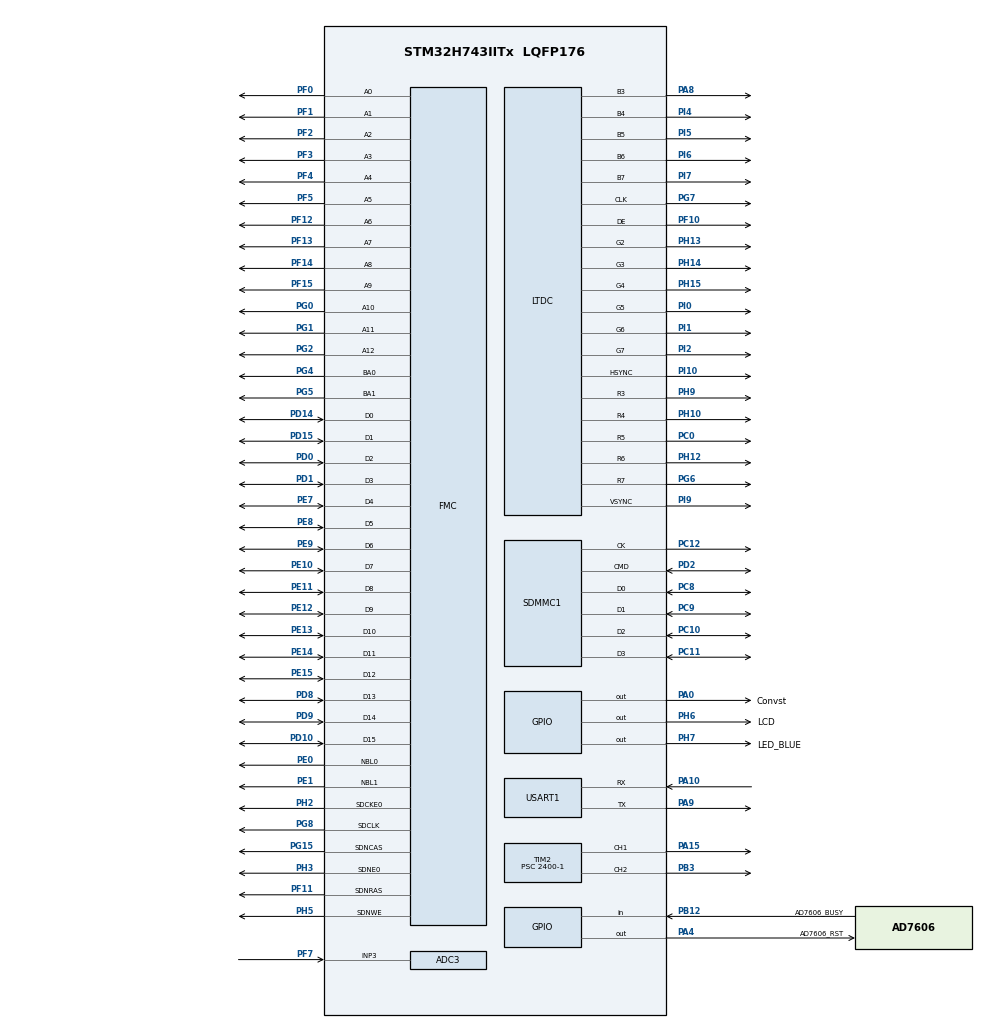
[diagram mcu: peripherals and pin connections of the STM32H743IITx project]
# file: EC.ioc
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ADC3.Channel-1\#ChannelRegularConversion=ADC_CHANNEL_3
ADC3.NbrOfConversionFlag=1
ADC3.OffsetNumber-1\#ChannelRegularConversion=ADC_OFFSET_NONE
ADC3.OffsetSignedSaturation-1\#ChannelRegularConversion=DISABLE
ADC3.Rank-1\#ChannelRegularConversion=1
ADC3.SamplingTime-1\#ChannelRegularConversion=ADC_SAMPLETIME_1CYCLE_5
Bdma.ADC3.0.Direction=DMA_PERIPH_TO_MEMORY
Bdma.ADC3.0.EventEnable=DISABLE
Bdma.ADC3.0.Instance=BDMA_Channel0
Bdma.ADC3.0.MemDataAlignment=DMA_MDATAALIGN_HALFWORD
Bdma.ADC3.0.MemInc=DMA_MINC_ENABLE
Bdma.ADC3.0.Mode=DMA_NORMAL
Bdma.ADC3.0.PeriphDataAlignment=DMA_PDATAALIGN_HALFWORD
Bdma.ADC3.0.PeriphInc=DMA_PINC_DISABLE
Bdma.ADC3.0.Polarity=HAL_DMAMUX_REQ_GEN_RISING
Bdma.ADC3.0.Priority=DMA_PRIORITY_LOW
Bdma.ADC3.0.RequestNumber=1
Bdma.ADC3.0.SignalID=NONE
Bdma.ADC3.0.SyncEnable=DISABLE
Bdma.ADC3.0.SyncPolarity=HAL_DMAMUX_SYNC_NO_EVENT
Bdma.ADC3.0.SyncRequestNumber=1
Bdma.ADC3.0.SyncSignalID=NONE
Bdma.Request0=ADC3
Bdma.RequestsNb=1
CORTEX_M7.AccessPermission-Cortex_Memory_Protection_Unit_Region2_Settings=MPU_REGION_FULL_ACCESS
CORTEX_M7.AccessPermission-Cortex_Memory_Protection_Unit_Region4_Settings=MPU_REGION_FULL_ACCESS
CORTEX_M7.BaseAddress-Cortex_Memory_Protection_Unit_Region2_Settings=0xC0000000
CORTEX_M7.BaseAddress-Cortex_Memory_Protection_Unit_Region4_Settings=0xC0000000
CORTEX_M7.CPU_DCache=Enabled
CORTEX_M7.CPU_ICache=Enabled
CORTEX_M7.Enable-Cortex_Memory_Protection_Unit_Region2_Settings=MPU_REGION_ENABLE
CORTEX_M7.Enable-Cortex_Memory_Protection_Unit_Region4_Settings=MPU_REGION_ENABLE
CORTEX_M7.IsCacheable-Cortex_Memory_Protection_Unit_Region2_Settings=MPU_ACCESS_CACHEABLE
CORTEX_M7.IsCacheable-Cortex_Memory_Protection_Unit_Region4_Settings=MPU_ACCESS_CACHEABLE
CORTEX_M7.MPU_Control=MPU_PRIVILEGED_DEFAULT
CORTEX_M7.Size-Cortex_Memory_Protection_Unit_Region2_Settings=MPU_REGION_SIZE_32MB
CORTEX_M7.Size-Cortex_Memory_Protection_Unit_Region4_Settings=MPU_REGION_SIZE_32MB
CORTEX_M7.SubRegionDisable-Cortex_Memory_Protection_Unit_Region2_Settings=0x00
DMA2D.ColorMode=DMA2D_OUTPUT_RGB565
DMA2D.Mode=DMA2D_R2M
FMC.CASLatency1=FMC_SDRAM_CAS_LATENCY_3
FMC.ColumnBitsNumber1=FMC_SDRAM_COLUMN_BITS_NUM_9
FMC.ExitSelfRefreshDelay1=7
FMC.LoadToActiveDelay1=2
FMC.RCDDelay1=2
FMC.RPDelay1=2
FMC.ReadBurst1=FMC_SDRAM_RBURST_ENABLE
FMC.ReadPipeDelay1=FMC_SDRAM_RPIPE_DELAY_1
FMC.RowCycleDelay1=7
FMC.SDClockPeriod1=FMC_SDRAM_CLOCK_PERIOD_2
FMC.SelfRefreshTime1=4
FMC.WriteRecoveryTime1=3
LTDC.ActiveH=272
LTDC.ActiveW=480
LTDC.Alpha_L0=255
LTDC.Alpha_L1=255
LTDC.BlendingFactor1_L1=LTDC_BLENDING_FACTOR1_PAxCA
LTDC.BlendingFactor2_L1=LTDC_BLENDING_FACTOR2_PAxCA
LTDC.Blue=0
LTDC.Blue_L0=0
LTDC.Blue_L1=0
LTDC.FBStartAdress_L0=0xC0000000
LTDC.FBStartAdress_L1=0xCC000000
LTDC.HBP=43
LTDC.HFP=8
LTDC.HSync=1
LTDC.ImageHeight_L0=272
LTDC.ImageHeight_L1=272
LTDC.ImageWidth_L0=480
LTDC.Layers=0
LTDC.PixelFormat_L0=LTDC_PIXEL_FORMAT_RGB565
LTDC.Red=0
LTDC.VBP=12
LTDC.VFP=8
LTDC.VSync=1
LTDC.WindowX1_L0=480
LTDC.WindowX1_L1=480
LTDC.WindowY1_L0=272
LTDC.WindowY1_L1=272
Mcu.Family=STM32H7
Mcu.Name=STM32H743IITx
Mcu.Package=LQFP176
NVIC.BDMA_Channel0_IRQn=true\:0\:0\:false\:false\:true\:false\:true
NVIC.DMA2D_IRQn=true\:6\:0\:true\:false\:true\:true\:true
NVIC.FMC_IRQn=true\:0\:0\:false\:false\:true\:true\:true
NVIC.LTDC_IRQn=true\:6\:0\:true\:false\:true\:true\:true
NVIC.PriorityGroup=NVIC_PRIORITYGROUP_4
NVIC.SDMMC1_IRQn=true\:0\:0\:false\:false\:true\:true\:true
NVIC.USART1_IRQn=true\:0\:0\:false\:false\:true\:true\:true
PA0.GPIO_Label=Convst
PA0.GPIO_PuPd=GPIO_NOPULL
PA0.Signal=GPIO_Output
PA10.GPIO_PuPd=GPIO_PULLUP
PA10.GPIO_Speed=GPIO_SPEED_FREQ_VERY_HIGH
PA10.Mode=Asynchronous
PA10.Signal=USART1_RX
PA13\ (JTMS/SWDIO).Mode=Serial_Wire
PA13\ (JTMS/SWDIO).Signal=DEBUG_JTMS-SWDIO
PA14\ (JTCK/SWCLK).Mode=Serial_Wire
PA14\ (JTCK/SWCLK).Signal=DEBUG_JTCK-SWCLK
PA15\ (JTDI).GPIO_PuPd=GPIO_NOPULL
PA15\ (JTDI).Signal=S_TIM2_CH1
PA2.Signal=LTDC_R1
PA4.GPIO_Label=AD7606_RST
PA4.Signal=GPIO_Output
PA8.Mode=RGB565
PA8.Signal=LTDC_B3
PA9.GPIO_PuPd=GPIO_PULLUP
PA9.GPIO_Speed=GPIO_SPEED_FREQ_VERY_HIGH
PA9.Mode=Asynchronous
PA9.Signal=USART1_TX
PB12.GPIO_Label=AD7606_BUSY
PB12.GPIO_PuPd=GPIO_NOPULL
PB12.Signal=GPIO_Input
PB3\ (JTDO/TRACESWO).GPIO_PuPd=GPIO_NOPULL
PB3\ (JTDO/TRACESWO).Signal=S_TIM2_CH2
PC0.Mode=RGB565
PC0.Signal=LTDC_R5
PC10.Mode=SD_4_bits_Wide_bus
PC10.Signal=SDMMC1_D2
PC11.Mode=SD_4_bits_Wide_bus
PC11.Signal=SDMMC1_D3
PC12.Mode=SD_4_bits_Wide_bus
PC12.Signal=SDMMC1_CK
PC8.GPIO_PuPd=GPIO_PULLUP
PC8.Mode=SD_4_bits_Wide_bus
PC8.Signal=SDMMC1_D0
PC9.Mode=SD_4_bits_Wide_bus
PC9.Signal=SDMMC1_D1
PD0.Signal=FMC_D2_DA2
PD1.Signal=FMC_D3_DA3
PD10.Signal=FMC_D15_DA15
PD14.Signal=FMC_D0_DA0
PD15.Signal=FMC_D1_DA1
PD2.Mode=SD_4_bits_Wide_bus
PD2.Signal=SDMMC1_CMD
PD6.Signal=LTDC_B2
PD8.Signal=FMC_D13_DA13
PD9.Signal=FMC_D14_DA14
PE0.Signal=FMC_NBL0
PE1.Signal=FMC_NBL1
PE10.Signal=FMC_D7_DA7
PE11.Signal=FMC_D8_DA8
PE12.Signal=FMC_D9_DA9
PE13.Signal=FMC_D10_DA10
PE14.Signal=FMC_D11_DA11
PE15.Signal=FMC_D12_DA12
PE6.Signal=LTDC_G1
PE7.Signal=FMC_D4_DA4
PE8.Signal=FMC_D5_DA5
PE9.Signal=FMC_D6_DA6
PF0.Signal=FMC_A0
PF1.Signal=FMC_A1
PF10.Mode=RGB565
PF10.Signal=LTDC_DE
PF11.Signal=FMC_SDNRAS
PF12.Signal=FMC_A6
PF13.Signal=FMC_A7
PF14.Signal=FMC_A8
PF15.Signal=FMC_A9
PF2.Signal=FMC_A2
PF3.Signal=FMC_A3
PF4.Signal=FMC_A4
PF5.Signal=FMC_A5
PF7.Mode=IN3-Single-Ended
PF7.Signal=ADC3_INP3
PG0.Signal=FMC_A10
PG1.Signal=FMC_A11
PG12.Signal=LTDC_B1
PG13.Signal=LTDC_R0
PG14.Signal=LTDC_B0
PG15.Signal=FMC_SDNCAS
PG2.Signal=FMC_A12
PG4.Signal=FMC_A14_BA0
PG5.Signal=FMC_A15_BA1
PG6.Mode=RGB565
PG6.Signal=LTDC_R7
PG7.Mode=RGB565
PG7.Signal=LTDC_CLK
PG8.Signal=FMC_SDCLK
PH0-OSC_IN\ (PH0).Mode=HSE-External-Oscillator
PH0-OSC_IN\ (PH0).Signal=RCC_OSC_IN
PH1-OSC_OUT\ (PH1).Mode=HSE-External-Oscillator
PH1-OSC_OUT\ (PH1).Signal=RCC_OSC_OUT
PH10.Mode=RGB565
PH10.Signal=LTDC_R4
PH12.Mode=RGB565
PH12.Signal=LTDC_R6
PH13.Mode=RGB565
PH13.Signal=LTDC_G2
PH14.Mode=RGB565
PH14.Signal=LTDC_G3
PH15.Mode=RGB565
PH15.Signal=LTDC_G4
PH2.Mode=SdramChipSelect1_1
PH2.Signal=FMC_SDCKE0
PH3.Mode=SdramChipSelect1_1
PH3.Signal=FMC_SDNE0
PH5.Signal=FMC_SDNWE
PH6.GPIO_Label=LCD
PH6.GPIO_ModeDefaultOutputPP=GPIO_MODE_OUTPUT_PP
PH6.GPIO_PuPd=GPIO_PULLUP
PH6.PinState=GPIO_PIN_SET
PH6.Signal=GPIO_Output
PH7.GPIO_Label=LED_BLUE
PH7.GPIO_PuPd=GPIO_PULLUP
PH7.Signal=GPIO_Output
PH8.Signal=LTDC_R2
PH9.Mode=RGB565
PH9.Signal=LTDC_R3
PI0.Mode=RGB565
PI0.Signal=LTDC_G5
PI1.Mode=RGB565
PI1.Signal=LTDC_G6
PI10.Mode=RGB565
PI10.Signal=LTDC_HSYNC
PI2.Mode=RGB565
PI2.Signal=LTDC_G7
PI4.Mode=RGB565
PI4.Signal=LTDC_B4
PI5.Mode=RGB565
PI5.Signal=LTDC_B5
PI6.Mode=RGB565
PI6.Signal=LTDC_B6
PI7.Mode=RGB565
PI7.Signal=LTDC_B7
PI9.Mode=RGB565
PI9.Signal=LTDC_VSYNC
ProjectManager.HeapSize=0x200
ProjectManager.StackSize=0x400
ProjectManager.TargetToolchain=SW4STM32
RCC.ADCFreq_Value=75000000
RCC.APB1Freq_Value=120000000
RCC.APB2Freq_Value=120000000
RCC.APB3Freq_Value=120000000
RCC.APB4Freq_Value=120000000
RCC.CortexFreq_Value=480000000
RCC.D1PPRE=RCC_APB3_DIV2
RCC.D2PPRE1=RCC_APB1_DIV2
RCC.D2PPRE2=RCC_APB2_DIV2
RCC.D3PPRE=RCC_APB4_DIV2
RCC.DIVM1=5
RCC.DIVM2=2
RCC.DIVM3=1
RCC.DIVN1=192
RCC.DIVN2=12
RCC.DIVN3=6
RCC.DIVQ1=4
RCC.DIVR3=1
RCC.FLatency=FLASH_LATENCY_4
RCC.HCLKFreq_Value=240000000
RCC.HPRE=RCC_HCLK_DIV2
RCC.PLL1_VCI_Range-AdvancedSettings=RCC_PLL1VCIRANGE_0
RCC.PLL2FRACN=0
RCC.PLL2_VCI_Range-AdvancedSettings=RCC_PLL2VCIRANGE_2
RCC.PLL2_VCO_SEL-AdvancedSettings=RCC_PLL2VCOMEDIUM
RCC.PLL3FRACN=0
RCC.PLL3_VCI_Range-AdvancedSettings=RCC_PLL3VCIRANGE_0
RCC.PLLFRACN=0
RCC.PLLSourceVirtual=RCC_PLLSOURCE_HSE
RCC.PWR_Regulator_Voltage_Scale=PWR_REGULATOR_VOLTAGE_SCALE0
RCC.SYSCLKFreq_VALUE=480000000
RCC.SYSCLKSource=RCC_SYSCLKSOURCE_PLLCLK
RCC.USBFreq_Value=240000000
SDMMC1.ClockDiv=2
SDMMC1.HardwareFlowControl=SDMMC_HARDWARE_FLOW_CONTROL_ENABLE
SH.FMC_A0.0=FMC_A0,13b-sda1
SH.FMC_A1.0=FMC_A1,13b-sda1
SH.FMC_A10.0=FMC_A10,13b-sda1
SH.FMC_A11.0=FMC_A11,13b-sda1
SH.FMC_A12.0=FMC_A12,13b-sda1
SH.FMC_A14_BA0.0=FMC_BA0,FourSdramBanks1
SH.FMC_A15_BA1.0=FMC_BA1,FourSdramBanks1
SH.FMC_A2.0=FMC_A2,13b-sda1
SH.FMC_A3.0=FMC_A3,13b-sda1
SH.FMC_A4.0=FMC_A4,13b-sda1
SH.FMC_A5.0=FMC_A5,13b-sda1
SH.FMC_A6.0=FMC_A6,13b-sda1
SH.FMC_A7.0=FMC_A7,13b-sda1
SH.FMC_A8.0=FMC_A8,13b-sda1
SH.FMC_A9.0=FMC_A9,13b-sda1
SH.FMC_D0_DA0.0=FMC_D0,sd-16b-d1
SH.FMC_D10_DA10.0=FMC_D10,sd-16b-d1
SH.FMC_D11_DA11.0=FMC_D11,sd-16b-d1
SH.FMC_D12_DA12.0=FMC_D12,sd-16b-d1
SH.FMC_D13_DA13.0=FMC_D13,sd-16b-d1
SH.FMC_D14_DA14.0=FMC_D14,sd-16b-d1
SH.FMC_D15_DA15.0=FMC_D15,sd-16b-d1
SH.FMC_D1_DA1.0=FMC_D1,sd-16b-d1
SH.FMC_D2_DA2.0=FMC_D2,sd-16b-d1
SH.FMC_D3_DA3.0=FMC_D3,sd-16b-d1
SH.FMC_D4_DA4.0=FMC_D4,sd-16b-d1
SH.FMC_D5_DA5.0=FMC_D5,sd-16b-d1
SH.FMC_D6_DA6.0=FMC_D6,sd-16b-d1
SH.FMC_D7_DA7.0=FMC_D7,sd-16b-d1
SH.FMC_D8_DA8.0=FMC_D8,sd-16b-d1
SH.FMC_D9_DA9.0=FMC_D9,sd-16b-d1
SH.FMC_NBL0.0=FMC_NBL0,Sd2ByteEnable1
SH.FMC_NBL1.0=FMC_NBL1,Sd2ByteEnable1
SH.FMC_SDCLK.0=FMC_SDCLK,13b-sda1
SH.FMC_SDNCAS.0=FMC_SDNCAS,13b-sda1
SH.FMC_SDNRAS.0=FMC_SDNRAS,13b-sda1
SH.FMC_SDNWE.0=FMC_SDNWE,13b-sda1
SH.S_TIM2_CH1.0=TIM2_CH1,PWM Generation1 CH1
SH.S_TIM2_CH2.0=TIM2_CH2,PWM Generation2 CH2
STMicroelectronics.X-CUBE-ALGOBUILD.1.2.1.LibraryCcDSPOoLibraryJjDSPOoLibrary=true
TIM2.Channel-PWM\ Generation1\ CH1=TIM_CHANNEL_1
TIM2.Channel-PWM\ Generation2\ CH2=TIM_CHANNEL_2
TIM2.Period=100
TIM2.Prescaler=2400-1
TIM2.Pulse-PWM\ Generation1\ CH1=1
TIM2.Pulse-PWM\ Generation2\ CH2=1
USART1.VirtualMode-Asynchronous=VM_ASYNC
VP_DMA2D_VS_DMA2D.Mode=DMA2D_Activate
VP_STMicroelectronics.X-CUBE-ALGOBUILD_VS_DSPOoLibraryJjLibrary_1.2.1_1.2.1.Mode=DSPOoLibraryJjLibrary
board=custom

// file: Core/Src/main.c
/* USER CODE BEGIN Header */
/**
  ******************************************************************************
  * @file           : main.c
  * @brief          : Main program body
  ******************************************************************************
  * @attention
  *
  * <h2><center>&copy; Copyright (c) 2021 STMicroelectronics.
  * All rights reserved.</center></h2>
  *
  * This software component is licensed by ST under Ultimate Liberty license
  * SLA0044, the "License"; You may not use this file except in compliance with
  * the License. You may obtain a copy of the License at:
  *                             www.st.com/SLA0044
  *
  ******************************************************************************
  */
/* USER CODE END Header */
#include "main.h"
#include "adc.h"
#include "bdma.h"
#include "dma2d.h"
#include "ltdc.h"
#include "sdmmc.h"
#include "tim.h"
#include "usart.h"
#include "gpio.h"
#include "fmc.h"

/* USER CODE BEGIN Includes */
#include "arm_math.h"
/* USER CODE END Includes */

void SystemClock_Config(void);
static void MPU_Config(void);

int main(void)
{

  /* MPU Configuration--------------------------------------------------------*/
  MPU_Config();

  /* Enable I-Cache---------------------------------------------------------*/
  SCB_EnableICache();

  /* Enable D-Cache---------------------------------------------------------*/
  SCB_EnableDCache();

  /* MCU Configuration--------------------------------------------------------*/

  /* Reset of all peripherals, Initializes the Flash interface and the Systick. */
  HAL_Init();

  /* Configure the system clock */
  SystemClock_Config();

  /* Initialize all configured peripherals */
  MX_GPIO_Init();
  MX_LTDC_Init();
  MX_FMC_Init();
  MX_DMA2D_Init();
  MX_USART1_UART_Init();
  MX_SDMMC1_SD_Init();
  MX_BDMA_Init();
  MX_ADC3_Init();
  MX_TIM2_Init();
  /* USER CODE BEGIN 2 */
    PowerPhaseRadians_f32
  /* USER CODE END 2 */

  /* Infinite loop */
  while (1)
  {

  }
}

void SystemClock_Config(void)
{
  RCC_OscInitTypeDef RCC_OscInitStruct = {0};
  RCC_ClkInitTypeDef RCC_ClkInitStruct = {0};

  /** Supply configuration update enable
  */
  HAL_PWREx_ConfigSupply(PWR_LDO_SUPPLY);
  /** Configure the main internal regulator output voltage
  */
  __HAL_PWR_VOLTAGESCALING_CONFIG(PWR_REGULATOR_VOLTAGE_SCALE0);

  while(!__HAL_PWR_GET_FLAG(PWR_FLAG_VOSRDY)) {}
  /** Macro to configure the PLL clock source
  */
  __HAL_RCC_PLL_PLLSOURCE_CONFIG(RCC_PLLSOURCE_HSE);
  /** Initializes the RCC Oscillators according to the specified parameters
  * in the RCC_OscInitTypeDef structure.
  */
  RCC_OscInitStruct.OscillatorType = RCC_OSCILLATORTYPE_HSE;
  RCC_OscInitStruct.HSEState = RCC_HSE_ON;
  RCC_OscInitStruct.PLL.PLLState = RCC_PLL_ON;
  RCC_OscInitStruct.PLL.PLLSource = RCC_PLLSOURCE_HSE;
  RCC_OscInitStruct.PLL.PLLM = 5;
  RCC_OscInitStruct.PLL.PLLN = 192;
  RCC_OscInitStruct.PLL.PLLP = 2;
  RCC_OscInitStruct.PLL.PLLQ = 4;
  RCC_OscInitStruct.PLL.PLLR = 2;
  RCC_OscInitStruct.PLL.PLLRGE = RCC_PLL1VCIRANGE_2;
  RCC_OscInitStruct.PLL.PLLVCOSEL = RCC_PLL1VCOWIDE;
  RCC_OscInitStruct.PLL.PLLFRACN = 0;
  if (HAL_RCC_OscConfig(&RCC_OscInitStruct) != HAL_OK)
  {
    Error_Handler();
  }
  /** Initializes the CPU, AHB and APB buses clocks
  */
  RCC_ClkInitStruct.ClockType = RCC_CLOCKTYPE_HCLK|RCC_CLOCKTYPE_SYSCLK
                              |RCC_CLOCKTYPE_PCLK1|RCC_CLOCKTYPE_PCLK2
                              |RCC_CLOCKTYPE_D3PCLK1|RCC_CLOCKTYPE_D1PCLK1;
  RCC_ClkInitStruct.SYSCLKSource = RCC_SYSCLKSOURCE_PLLCLK;
  RCC_ClkInitStruct.SYSCLKDivider = RCC_SYSCLK_DIV1;
  RCC_ClkInitStruct.AHBCLKDivider = RCC_HCLK_DIV2;
  RCC_ClkInitStruct.APB3CLKDivider = RCC_APB3_DIV2;
  RCC_ClkInitStruct.APB1CLKDivider = RCC_APB1_DIV2;
  RCC_ClkInitStruct.APB2CLKDivider = RCC_APB2_DIV2;
  RCC_ClkInitStruct.APB4CLKDivider = RCC_APB4_DIV2;

  if (HAL_RCC_ClockConfig(&RCC_ClkInitStruct, FLASH_LATENCY_4) != HAL_OK)
  {
    Error_Handler();
  }
}

/* MPU Configuration */

void MPU_Config(void)
{
  MPU_Region_InitTypeDef MPU_InitStruct = {0};

  /* Disables the MPU */
  HAL_MPU_Disable();
  /** Initializes and configures the Region and the memory to be protected
  */
  MPU_InitStruct.Enable = MPU_REGION_ENABLE;
  MPU_InitStruct.Number = MPU_REGION_NUMBER2;
  MPU_InitStruct.BaseAddress = 0xC0000000;
  MPU_InitStruct.Size = MPU_REGION_SIZE_32MB;
  MPU_InitStruct.SubRegionDisable = 0x00;
  MPU_InitStruct.TypeExtField = MPU_TEX_LEVEL0;
  MPU_InitStruct.AccessPermission = MPU_REGION_FULL_ACCESS;
  MPU_InitStruct.DisableExec = MPU_INSTRUCTION_ACCESS_ENABLE;
  MPU_InitStruct.IsShareable = MPU_ACCESS_NOT_SHAREABLE;
  MPU_InitStruct.IsCacheable = MPU_ACCESS_CACHEABLE;
  MPU_InitStruct.IsBufferable = MPU_ACCESS_NOT_BUFFERABLE;

  HAL_MPU_ConfigRegion(&MPU_InitStruct);
  /** Initializes and configures the Region and the memory to be protected
  */
  MPU_InitStruct.Number = MPU_REGION_NUMBER4;
  MPU_InitStruct.SubRegionDisable = 0x0;

  HAL_MPU_ConfigRegion(&MPU_InitStruct);
  /* Enables the MPU */
  HAL_MPU_Enable(MPU_PRIVILEGED_DEFAULT);

}

void Error_Handler(void)
{
  __disable_irq();
  while (1)
  {
  }
}

/************************ (C) COPYRIGHT STMicroelectronics *****END OF FILE****/
